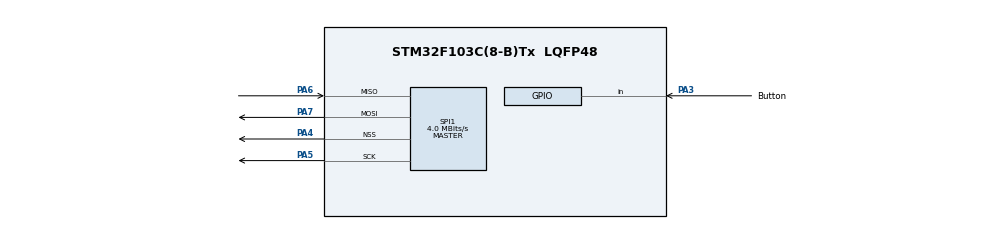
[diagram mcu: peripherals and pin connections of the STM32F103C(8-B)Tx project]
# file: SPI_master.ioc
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Mcu.Family=STM32F1
Mcu.Name=STM32F103C(8-B)Tx
Mcu.Package=LQFP48
NVIC.PriorityGroup=NVIC_PRIORITYGROUP_4
NVIC.SPI1_IRQn=true\:0\:0\:false\:false\:true\:true\:true\:true
PA13.Mode=Serial_Wire
PA13.Signal=SYS_JTMS-SWDIO
PA14.Mode=Serial_Wire
PA14.Signal=SYS_JTCK-SWCLK
PA3.GPIO_Label=Button
PA3.GPIO_PuPd=GPIO_PULLUP
PA3.Signal=GPIO_Input
PA4.Mode=NSS_Signal_Hard_Output
PA4.Signal=SPI1_NSS
PA5.Mode=Full_Duplex_Master
PA5.Signal=SPI1_SCK
PA6.Mode=Full_Duplex_Master
PA6.Signal=SPI1_MISO
PA7.Mode=Full_Duplex_Master
PA7.Signal=SPI1_MOSI
ProjectManager.HeapSize=0x200
ProjectManager.StackSize=0x400
ProjectManager.TargetToolchain=Makefile
RCC.APB1Freq_Value=8000000
RCC.APB2Freq_Value=8000000
SPI1.BaudRatePrescaler=SPI_BAUDRATEPRESCALER_2
SPI1.CalculateBaudRate=4.0 MBits/s
SPI1.Direction=SPI_DIRECTION_2LINES
SPI1.Mode=SPI_MODE_MASTER
SPI1.VirtualNSS=VM_NSSHARD
SPI1.VirtualType=VM_MASTER
board=custom

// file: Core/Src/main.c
/* USER CODE BEGIN Header */
/**
  ******************************************************************************
  * @file           : main.c
  * @brief          : Main program body
  ******************************************************************************
  * @attention
  *
  * Copyright (c) 2022 STMicroelectronics.
  * All rights reserved.
  *
  * This software is licensed under terms that can be found in the LICENSE file
  * in the root directory of this software component.
  * If no LICENSE file comes with this software, it is provided AS-IS.
  *
  ******************************************************************************
  */
/* USER CODE END Header */
#include "main.h"
#include "spi.h"
#include "gpio.h"

/* USER CODE BEGIN PV */
uint8_t Txbuffer = 0;
/* USER CODE END PV */

void SystemClock_Config(void);

int main(void)
{

  /* MCU Configuration--------------------------------------------------------*/

  /* Reset of all peripherals, Initializes the Flash interface and the Systick. */
  HAL_Init();

  /* Configure the system clock */
  SystemClock_Config();

  /* Initialize all configured peripherals */
  MX_GPIO_Init();
  MX_SPI1_Init();

  /* Infinite loop */
  while (1)
  {

    /* USER CODE BEGIN 3 */
    if(HAL_GPIO_ReadPin(Button_GPIO_Port, Button_Pin) == 0)
    {
      HAL_Delay(20);
      if(HAL_GPIO_ReadPin(Button_GPIO_Port, Button_Pin) == 0)
      {
        Txbuffer = (Txbuffer == 1)?0:1;
        HAL_GPIO_WritePin(GPIOA, GPIO_PIN_4, 0);
        HAL_SPI_Transmit(&hspi1, &Txbuffer, 1, 100);
        HAL_GPIO_WritePin(GPIOA, GPIO_PIN_4, 1);
      }
    }
  }
  /* USER CODE END 3 */
}

void SystemClock_Config(void)
{
  RCC_OscInitTypeDef RCC_OscInitStruct = {0};
  RCC_ClkInitTypeDef RCC_ClkInitStruct = {0};

  /** Initializes the RCC Oscillators according to the specified parameters
  * in the RCC_OscInitTypeDef structure.
  */
  RCC_OscInitStruct.OscillatorType = RCC_OSCILLATORTYPE_HSI;
  RCC_OscInitStruct.HSIState = RCC_HSI_ON;
  RCC_OscInitStruct.HSICalibrationValue = RCC_HSICALIBRATION_DEFAULT;
  RCC_OscInitStruct.PLL.PLLState = RCC_PLL_NONE;
  if (HAL_RCC_OscConfig(&RCC_OscInitStruct) != HAL_OK)
  {
    Error_Handler();
  }

  /** Initializes the CPU, AHB and APB buses clocks
  */
  RCC_ClkInitStruct.ClockType = RCC_CLOCKTYPE_HCLK|RCC_CLOCKTYPE_SYSCLK
                              |RCC_CLOCKTYPE_PCLK1|RCC_CLOCKTYPE_PCLK2;
  RCC_ClkInitStruct.SYSCLKSource = RCC_SYSCLKSOURCE_HSI;
  RCC_ClkInitStruct.AHBCLKDivider = RCC_SYSCLK_DIV1;
  RCC_ClkInitStruct.APB1CLKDivider = RCC_HCLK_DIV1;
  RCC_ClkInitStruct.APB2CLKDivider = RCC_HCLK_DIV1;

  if (HAL_RCC_ClockConfig(&RCC_ClkInitStruct, FLASH_LATENCY_0) != HAL_OK)
  {
    Error_Handler();
  }
}

void Error_Handler(void)
{
  __disable_irq();
  while (1)
  {
  }
}
